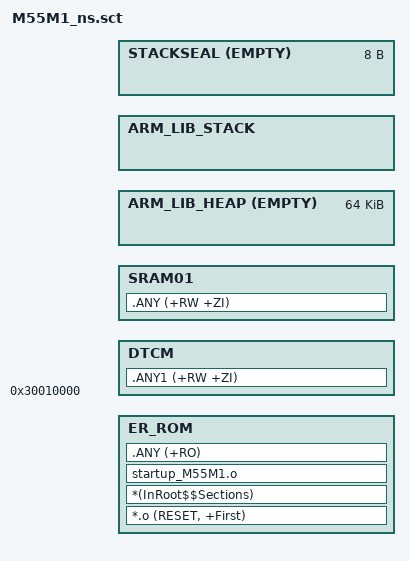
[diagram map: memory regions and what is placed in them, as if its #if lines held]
#! armclang -E --target=arm-arm-none-eabi -mcpu=cortex-m55 -xc
; command above MUST be in first line (no comment above!)

; Note: If any modification needed, please copy to local project folder first.
; Note: Add '-mcmse' to first line if your software model is "Secure Mode".
;       #! armclang -E --target=arm-arm-none-eabi -mcpu=cortex-m55 -xc -mcmse

/* https://github.com/ARM-software/CMSIS_5/tree/develop/Device/ARM/ARMCM55/Source/ARM */

/*
 * This is a simplified picture of the NuMicro TC8263 memory system.
 * Please refer to the NuMicro TC8263 Technical Reference Manual for
 * further information.
 *
 *
 * +---------------+   +---------------+  +--------------------------+
 * | Ethos-U55     |   | Cortex-M55    +--+ ITCM (Shared with SRAM2) |
 * |               |   |               |  +--------------------------+
 * |               |   |               |
 * |               |   |               |  +--------------------------+ 
 * |  M1      M0   |   |               +--+ DTCM (Shared with SRAM2) |
 * +---+-------+---+   +-------+-------+  +--------------------------+
 *     |       |               |
 *     |   +---+---------------+-------+
 *     |   |   AMBA AXI NIC-400-Lite   |
 *     |   +---+--------+---------+----+
 *     |       |        |         |
 * +---+-------+--+ +---+---+ +---+---+
 * | AMBA AHB     | | SRAM0 | | SRAM2 |
 * +---+----------+ | SRAM1 | +-------+
 *     |            +-------+
 * +---+---+ 
 * | FLASH |
 * +-------+
 *
 * +-----------------------+-------------+-------------+----+------------------------------------------------+
 * |  Memory region name   | Base addr   |    Size     |IDAU| Description                                    |
 * +-----------------------+-------------+-------------+----+------------------------------------------------+
 * | ITCM                  | 0x0000_0000 | 0x0001_0000 | S  | 128 kiB; Shared with SRAM2                     |
 * | ITCM                  | 0x1000_0000 | 0x0001_0000 | NS | Non-Secure alias for ITCM                      |
 * | FLASH                 | 0x0010_0000 | 0x0020_0000 | S  | 2 MiB                                          |
 * | FLASH                 | 0x1010_0000 | 0x0020_0000 | NS | Non-Secure alias for Flash                     |
 * | DTCM                  | 0x2000_0000 | 0x0002_0000 | S  | 128 kiB; Shared with SRAM2                     |
 * | DTCM                  | 0x3000_0000 | 0x0002_0000 | NS | Non-Secure alias for DTCM                      |
 * | SRAM01                | 0x2010_0000 | 0x0010_0000 | S  | 2 banks of 512 kiB; (3cc latency)              |
 * | SRAM01                | 0x3010_0000 | 0x0010_0000 | NS | Non-Secure alias for SRAM01                    |
 * | SRAM2                 | 0x2020_0000 | 0x0008_0000 | S  | 512 kiB                                        |
 * | SRAM2                 | 0x3020_0000 | 0x0008_0000 | NS | Non-Secure alias for SRAM2                     |
 * | SRAM3                 | 0x2030_0000 | 0x0002_0000 | S  | 512 kiB                                        |
 * | SRAM3                 | 0x3030_0000 | 0x0002_0000 | NS | Non-Secure alias for SRAM3                     |
 * | LPSRAM                | 0x2031_0000 | 0x0008_0000 | S  | 512 kiB                                        |
 * | LPSRAM                | 0x3031_0000 | 0x0008_0000 | NS | Non-Secure alias for LPSRAM                    |
 * | EBI                   | 0x6000_0000 | 0x0030_0000 | S  | 3 MiB                                          |
 * | EBI                   | 0x7000_0000 | 0x0030_0000 | NS | Non-Secure alias for EBI                       |
 * | SPIM0                 | 0x8000_0000 | 0x0200_0000 | S  | 32 MiB                                         |
 * | SPIM0                 | 0x9000_0000 | 0x0200_0000 | NS | Non-Secure alias for SPIM0                     |
 * | SPIM1                 | 0x8200_0000 | 0x0200_0000 | S  | 32 MiB                                         |
 * | SPIM1                 | 0x9200_0000 | 0x0200_0000 | NS | Non-Secure alias for SPIM1                     |
 * +-----------------------+-------------+-------------+----+------------------------------------------------+
 *
 *  Note: Ethos-U55 can access Flash, internal SRAM 0,1 => activation buffers and
 *        the model should only be placed in those regions.
 *
 *  Note: Alias regions means that secure and non-secure addresses are mapped to the same physical
 *        memory banks.
 */
#include "partition_M55M1.h"

#ifndef STACK_SIZE
#define STACK_SIZE      0x00008000
#endif

#ifndef HEAP_SIZE
#define HEAP_SIZE       0x00010000
#endif

#define FLASH_START     FMC_NON_SECURE_BASE
#define FLASH_SIZE      (0x00200000 - FMC_SECURE_REGION_SIZE)
#define SRAM01_START    NON_SECURE_SRAM_BASE
//#define SRAM01_START    0x30180000
#define SRAM01_END      0x301FFFFF
#define SRAM01_SIZE	    (SRAM01_END + 1 - SRAM01_START)

#define ITCM_START      0x10008000
#define DTCM_START      0x30010000

/*Non-security memory region*/
#define SRAM2_START     0x30200000
#define SRAM2_SIZE      (0x80000 - CFG_ITCM_SIZE - CFG_DTCM_SIZE)
#define SRAM3_START     0x30300000
#define SRAM3_SIZE      0x2000

#define SPIM0_START     0x90000000
#define SPIM0_SIZE      0x02000000
#define SPIM1_START     0x92000000
#define SPIM1_SIZE      0x02000000


/*----------------------------------------------------------------------------
  User Stack & Heap boundary definition
 *----------------------------------------------------------------------------*/
#define __STACK_TOP    (SRAM01_START + SRAM01_SIZE - __STACKSEAL_SIZE)  /* starts at end of RAM - 8 byte stack seal */
#define __HEAP_BASE    (AlignExpr(+0, 8))                               /* starts after RW_RAM section, 8 byte aligned */

/* ----------------------------------------------------------------------------
  Stack seal size definition
 *----------------------------------------------------------------------------*/
#if defined (__ARM_FEATURE_CMSE) && (__ARM_FEATURE_CMSE == 3U)
#define __STACKSEAL_SIZE   ( 8 )
#else
#define __STACKSEAL_SIZE   ( 0 )
#endif


/*----------------------------------------------------------------------------
  Region base & size definition
 *----------------------------------------------------------------------------*/
#if defined (__ARM_FEATURE_CMSE) && (__ARM_FEATURE_CMSE == 3U)
#define TZ_NSC_START        ( FLASH_START + FLASH_SIZE - __CMSEVENEER_SIZE )
#define TZ_NSC_SIZE         ( __CMSEVENEER_SIZE )
#else
#define TZ_NSC_SIZE         ( 0 )
#endif

#define __RO_BASE           ( FLASH_START )
#define __RO_SIZE           ( FLASH_SIZE - TZ_NSC_SIZE )

#define __RW_BASE           ( SRAM01_START )
#define __RW_SIZE           ( SRAM01_SIZE - STACK_SIZE - HEAP_SIZE )


/*----------------------------------------------------------------------------
  Scatter Region definition
 *----------------------------------------------------------------------------*/
LR_ROM __RO_BASE __RO_SIZE  {                       ; load region size_region
    ER_ROM __RO_BASE __RO_SIZE  {                   ; load address = execution address
        *.o (RESET, +First)
        *(InRoot$$Sections)
        ; Make sure reset_handler ends up in root segment
        startup_M55M1.o
        .ANY (+RO)
    }
	
	; DTCM 128 KB shared with SRAM2
    ; Only accessible from the Cortex-M
#if (DTCM_SIZE > (STACK_SIZE + HEAP_SIZE + __STACKSEAL_SIZE))
    DTCM DTCM_START (DTCM_SIZE - STACK_SIZE - HEAP_SIZE - __STACKSEAL_SIZE)
    {
        .ANY1 (+RW +ZI)
    }
#endif

    ; 1 MB SRAM01 (3 cycles read latency) from M55/U55
    SRAM01 __RW_BASE __RW_SIZE              ; RW data
    {
        .ANY (+RW +ZI)
	}

#if HEAP_SIZE > 0
    ARM_LIB_HEAP  __HEAP_BASE EMPTY  HEAP_SIZE {}		; Reserve empty region for heap
#endif


    ARM_LIB_STACK __STACK_TOP EMPTY - STACK_SIZE {}     ; Reserve empty region for stack

#if defined (__ARM_FEATURE_CMSE) && (__ARM_FEATURE_CMSE == 3U)
STACKSEAL +0 EMPTY __STACKSEAL_SIZE {
        ; Reserve empty region for stack seal immediately after stack
    }
#endif
}
